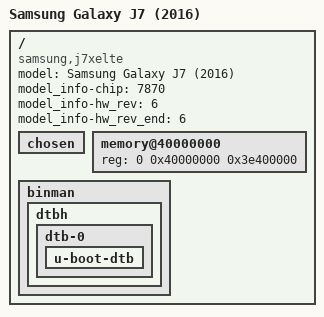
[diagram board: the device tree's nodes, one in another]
// SPDX-License-Identifier: GPL-2.0+

/dts-v1/;

/ {
	#address-cells = <2>;
	#size-cells = <1>;
	model = "Samsung Galaxy J7 (2016)";
	compatible = "samsung,j7xelte", "samsung,exynos7870";
	model_info-chip = <7870>;
	model_info-hw_rev = <6>;
	model_info-hw_rev_end = <6>;

	chosen {
	};

	memory@40000000 {
		device_type = "memory";
		reg = <0 0x40000000 0x3e400000>;
	};

	binman {
		dtbh {
			dtb-0 {
				u-boot-dtb {};
			};
		};
	};
};
